# STM32H750 register map
File version: 2.7
CPU: CM7 r0p1, little endian, MPU, FPU, 4 interrupt priority bits
Registers are 32-bit, read-write, reset 0x0 unless marked. A register's access mark holds for its fields unless they carry their own. Offsets are from the block's base; [hi:lo] are bit positions; lines under a group give offsets from that group; {n}, {i} and the like mark numbered series.

## HASH — Hash processor
Base 0x48021400
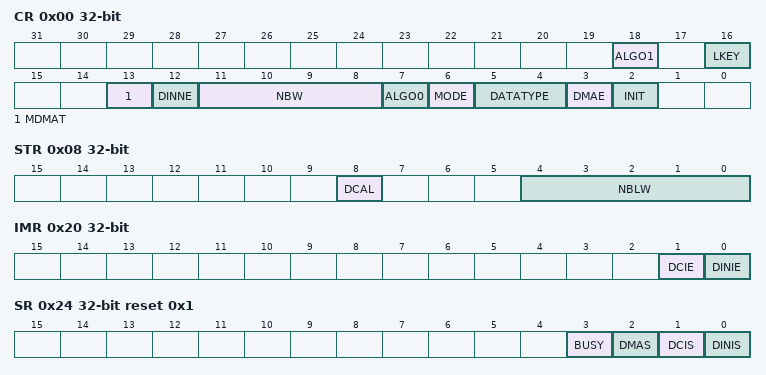
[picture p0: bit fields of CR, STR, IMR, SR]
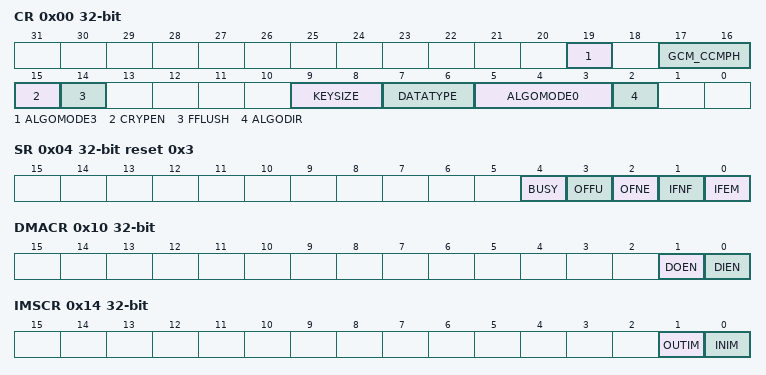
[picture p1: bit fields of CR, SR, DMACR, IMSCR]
0x00 CR access per field — control register
  [18] ALGO1 rw — ALGO
  [16] LKEY rw — Long key selection
  [13] MDMAT rw — Multiple DMA Transfers
  [12] DINNE ro — DIN not empty
  [11:8] NBW ro — Number of words already pushed
  [7] ALGO0 rw — Algorithm selection
  [6] MODE rw — Mode selection
  [5:4] DATATYPE rw — Data type selection
  [3] DMAE rw — DMA enable
  [2] INIT wo — Initialize message digest calculation
0x04 DIN — data input register
  [31:0] DATAIN — Data input
0x08 STR access per field — start register
  [8] DCAL wo — Digest calculation
  [4:0] NBLW rw — Number of valid bits in the last word of the message
{0xC+4i} HR{i} (i=0..4) ro — digest registers
  [31:0] H — H0
0x20 IMR — interrupt enable register
  [1] DCIE — Digest calculation completion interrupt enable
  [0] DINIE — Data input interrupt enable
0x24 SR access per field reset 0x1 — status register
  [3] BUSY ro — Busy bit
  [2] DMAS ro — DMA Status
  [1] DCIS rw — Digest calculation completion interrupt status
  [0] DINIS rw — Data input interrupt status
{0xF8+4i} CSR{i} (i=0..53) — context swap registers
  [31:0] CSR — CSR0
{0x310+4i} HASH_HR{i} (i=0..7) ro — HASH digest register {i}
  [31:0] H — H0

## CRYP — Cryptographic processor
Base 0x48021000
0x00 CR access per field — control register
  [19] ALGOMODE3 rw — ALGOMODE
  [17:16] GCM_CCMPH rw
  [15] CRYPEN rw — Cryptographic processor enable
  [14] FFLUSH wo — FIFO flush
  [9:8] KEYSIZE rw — Key size selection (AES mode only)
  [7:6] DATATYPE rw — Data type selection
  [5:3] ALGOMODE0 rw — Algorithm mode
  [2] ALGODIR rw — Algorithm direction
0x04 SR ro reset 0x3 — status register
  [4] BUSY — Busy bit
  [3] OFFU — Output FIFO full
  [2] OFNE — Output FIFO not empty
  [1] IFNF — Input FIFO not full
  [0] IFEM — Input FIFO empty
0x08 DIN — data input register
  [31:0] DATAIN — Data input
0x0C DOUT ro — data output register
  [31:0] DATAOUT — Data output
0x10 DMACR — DMA control register
  [1] DOEN — DMA output enable
  [0] DIEN — DMA input enable
0x14 IMSCR — interrupt mask set/clear register
  [1] OUTIM — Output FIFO service interrupt mask
  [0] INIM — Input FIFO service interrupt mask
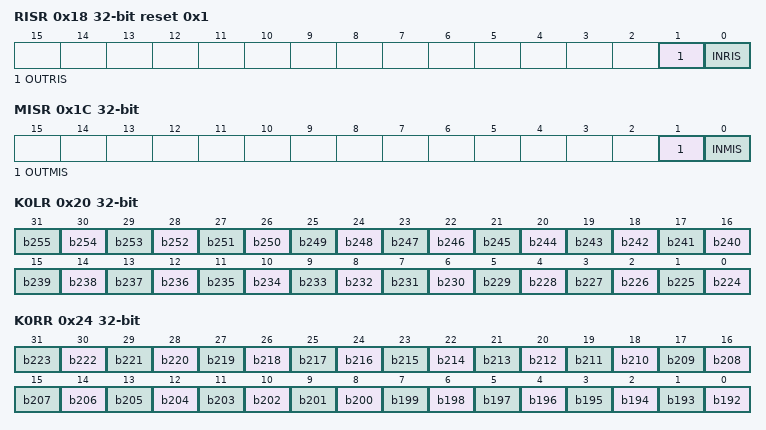
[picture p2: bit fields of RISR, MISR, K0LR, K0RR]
0x18 RISR ro reset 0x1 — raw interrupt status register
  [1] OUTRIS — Output FIFO service raw interrupt status
  [0] INRIS — Input FIFO service raw interrupt status
0x1C MISR ro — masked interrupt status register
  [1] OUTMIS — Output FIFO service masked interrupt status
  [0] INMIS — Input FIFO service masked interrupt status
0x20 K0LR wo — key registers
  [n-224] b{n} (n=224..255)
0x24 K0RR wo — key registers
  [n-192] b{n} (n=192..223)
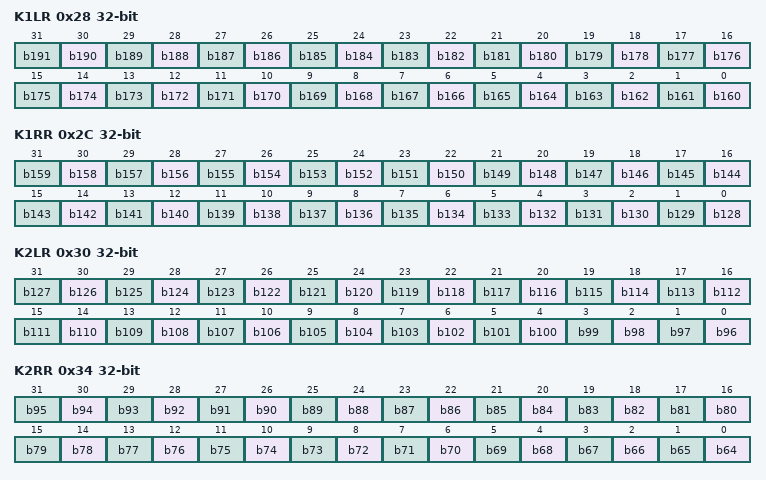
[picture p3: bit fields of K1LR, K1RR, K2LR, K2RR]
0x28 K1LR wo — key registers
  [n-160] b{n} (n=160..191)
0x2C K1RR wo — key registers
  [n-128] b{n} (n=128..159)
0x30 K2LR wo — key registers
  [n-96] b{n} (n=96..127)
0x34 K2RR wo — key registers
  [n-64] b{n} (n=64..95)
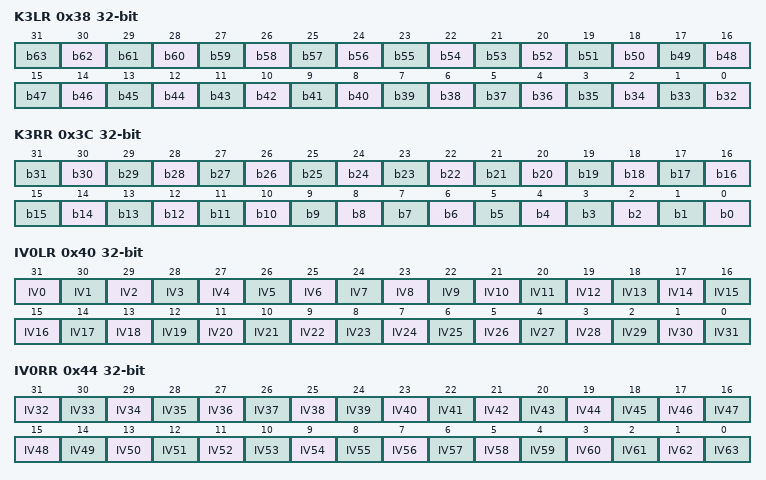
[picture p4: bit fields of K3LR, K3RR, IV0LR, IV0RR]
0x38 K3LR wo — key registers
  [n-32] b{n} (n=32..63)
0x3C K3RR wo — key registers
  [n] b{n} (n=0..31)
0x40 IV0LR — initialization vector registers
  [31-n] IV{n} (n=0..31)
0x44 IV0RR — initialization vector registers
  [63-n] IV{n} (n=32..63)
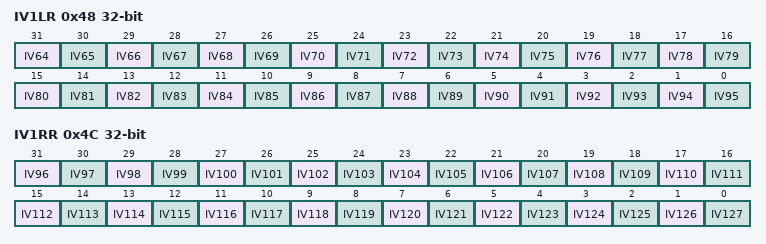
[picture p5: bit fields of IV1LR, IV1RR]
0x48 IV1LR — initialization vector registers
  [95-n] IV{n} (n=64..95)
0x4C IV1RR — initialization vector registers
  [127-n] IV{n} (n=96..127)
{0x50+4i} CSGCMCCM{i}R (i=0..7) — context swap register
{0x70+4i} CSGCM{i}R (i=0..7) — context swap register

## OTG1_HS_HOST — USB 1 on the go high speed
Base 0x40040400
Same registers: OTG2_HS_HOST 0x40080400
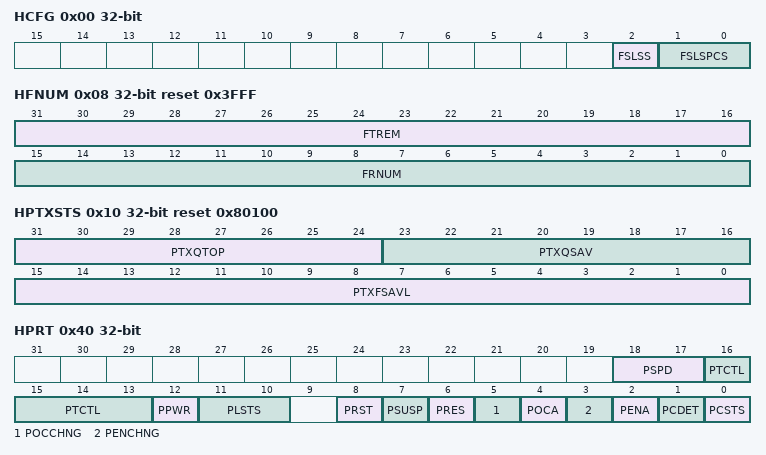
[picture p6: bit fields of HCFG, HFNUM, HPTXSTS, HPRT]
0x00 HCFG access per field — OTG_HS host configuration register
  [2] FSLSS ro — FS- and LS-only support
  [1:0] FSLSPCS rw — FS/LS PHY clock select
0x04 HFIR reset 0xEA60 — OTG_HS Host frame interval register
  [15:0] FRIVL — Frame interval
0x08 HFNUM ro reset 0x3FFF — OTG_HS host frame number/frame time remaining register
  [31:16] FTREM — Frame time remaining
  [15:0] FRNUM — Frame number
0x10 HPTXSTS access per field reset 0x80100 — OTG_HS_Host periodic transmit FIFO/queue status register
  [31:24] PTXQTOP ro — Top of the periodic transmit request queue
  [23:16] PTXQSAV ro — Periodic transmit request queue space available
  [15:0] PTXFSAVL rw — Periodic transmit data FIFO space available
0x14 HAINT ro — OTG_HS Host all channels interrupt register
  [15:0] HAINT — Channel interrupts
0x18 HAINTMSK — OTG_HS host all channels interrupt mask register
  [15:0] HAINTM — Channel interrupt mask
0x40 HPRT access per field — OTG_HS host port control and status register
  [18:17] PSPD ro — Port speed
  [16:13] PTCTL rw — Port test control
  [12] PPWR rw — Port power
  [11:10] PLSTS ro — Port line status
  [8] PRST rw — Port reset
  [7] PSUSP rw — Port suspend
  [6] PRES rw — Port resume
  [5] POCCHNG rw — Port overcurrent change
  [4] POCA ro — Port overcurrent active
  [3] PENCHNG rw — Port enable/disable change
  [2] PENA rw — Port enable
  [1] PCDET rw — Port connect detected
  [0] PCSTS ro — Port connect status
{0x100+0x20*i} HC{i} (i=0..15) group — Host channel
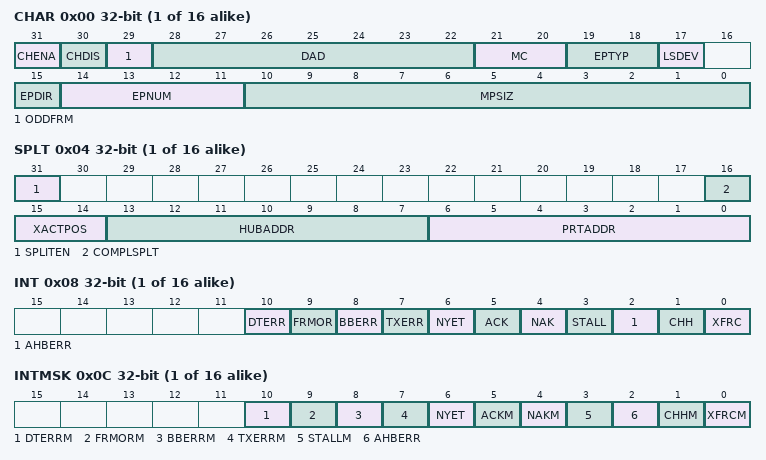
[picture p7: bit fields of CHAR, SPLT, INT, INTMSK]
  0x00 CHAR — OTG_HS host channel-0 characteristics register
    [31] CHENA — Channel enable
    [30] CHDIS — Channel disable
    [29] ODDFRM — Odd frame
    [28:22] DAD — Device address
    [21:20] MC — Multi Count (MC) / Error Count (EC)
    [19:18] EPTYP — Endpoint type
    [17] LSDEV — Low-speed device
    [15] EPDIR — Endpoint direction
    [14:11] EPNUM — Endpoint number
    [10:0] MPSIZ — Maximum packet size
  0x04 SPLT — OTG_HS host channel-0 split control register
    [31] SPLITEN — Split enable
    [16] COMPLSPLT — Do complete split
    [15:14] XACTPOS
    [13:7] HUBADDR — Hub address
    [6:0] PRTADDR — Port address
  0x08 INT — OTG_HS host channel-11 interrupt register
    [10] DTERR — Data toggle error
    [9] FRMOR — Frame overrun
    [8] BBERR — Babble error
    [7] TXERR — Transaction error
    [6] NYET — Response received interrupt
    [5] ACK — ACK response received/transmitted interrupt
    [4] NAK — NAK response received interrupt
    [3] STALL — STALL response received interrupt
    [2] AHBERR — AHB error
    [1] CHH — Channel halted
    [0] XFRC — Transfer completed
  0x0C INTMSK — OTG_HS host channel-11 interrupt mask register
    [10] DTERRM — Data toggle error mask
    [9] FRMORM — Frame overrun mask
    [8] BBERRM — Babble error mask
    [7] TXERRM — Transaction error mask
    [6] NYET — response received interrupt mask
    [5] ACKM — ACK response received/transmitted interrupt mask
    [4] NAKM — NAK response received interrupt mask
    [3] STALLM — STALL response received interrupt mask
    [2] AHBERR — AHB error
    [1] CHHM — Channel halted mask
    [0] XFRCM — Transfer completed mask
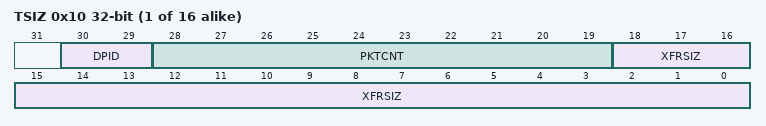
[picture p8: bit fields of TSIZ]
  0x10 TSIZ — OTG_HS host channel-11 transfer size register
    [30:29] DPID — Data PID
    [28:19] PKTCNT — Packet count
    [18:0] XFRSIZ — Transfer size
  0x14 DMA — OTG_HS host channel-0 DMA address register
    [31:0] DMAADDR — DMA address
